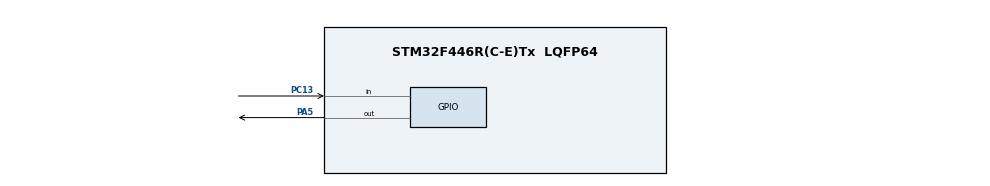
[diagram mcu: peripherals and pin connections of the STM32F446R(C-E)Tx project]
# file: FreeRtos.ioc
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FREERTOS.Mutexes01=myMutex01,Dynamic,NULL
FREERTOS.Tasks01=Task1,40,128,StartTask1,Default,NULL,Dynamic,NULL,NULL;Task2,24,128,StartTask2,Default,NULL,Dynamic,NULL,NULL;Task3,8,128,StartTask3,Default,NULL,Dynamic,NULL,NULL
Mcu.Family=STM32F4
Mcu.Name=STM32F446R(C-E)Tx
Mcu.Package=LQFP64
NVIC.PriorityGroup=NVIC_PRIORITYGROUP_4
NVIC.TIM6_DAC_IRQn=true\:15\:0\:false\:false\:true\:false\:false\:true\:true
NVIC.TimeBase=TIM6_DAC_IRQn
NVIC.TimeBaseIP=TIM6
PA13.Mode=Trace_Asynchronous_SW
PA13.Signal=SYS_JTMS-SWDIO
PA14.Mode=Trace_Asynchronous_SW
PA14.Signal=SYS_JTCK-SWCLK
PA5.Signal=GPIO_Output
PB3.Mode=Trace_Asynchronous_SW
PB3.Signal=SYS_JTDO-SWO
PC13.Signal=GPIO_Input
ProjectManager.HeapSize=0x200
ProjectManager.StackSize=0x400
ProjectManager.TargetToolchain=STM32CubeIDE
RCC.CortexFreq_Value=16000000
RCC.USBFreq_Value=96000000
RCC.VCOOutputFreq_Value=192000000
VP_FREERTOS_VS_CMSIS_V2.Mode=CMSIS_V2
VP_SYS_VS_tim6.Mode=TIM6
board=custom

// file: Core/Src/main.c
/* USER CODE BEGIN Header */
/**
  ******************************************************************************
  * @file           : main.c
  * @brief          : Main program body
  ******************************************************************************
  * @attention
  *
  * Copyright (c) 2024 STMicroelectronics.
  * All rights reserved.
  *
  * This software is licensed under terms that can be found in the LICENSE file
  * in the root directory of this software component.
  * If no LICENSE file comes with this software, it is provided AS-IS.
  *
  ******************************************************************************
  */
/* USER CODE END Header */
#include "main.h"
#include "cmsis_os.h"

/* USER CODE BEGIN Includes */
#include <stdio.h>

/* USER CODE END Includes */

/* Definitions for Task1 */
osThreadId_t Task1Handle;
const osThreadAttr_t Task1_attributes = {
  .name = "Task1",
  .stack_size = 128 * 4,
  .priority = (osPriority_t) osPriorityHigh,
};
/* Definitions for Task2 */
osThreadId_t Task2Handle;
const osThreadAttr_t Task2_attributes = {
  .name = "Task2",
  .stack_size = 128 * 4,
  .priority = (osPriority_t) osPriorityNormal,
};
/* Definitions for Task3 */
osThreadId_t Task3Handle;
const osThreadAttr_t Task3_attributes = {
  .name = "Task3",
  .stack_size = 128 * 4,
  .priority = (osPriority_t) osPriorityLow,
};
/* Definitions for myMutex01 */
osMutexId_t myMutex01Handle;
const osMutexAttr_t myMutex01_attributes = {
  .name = "myMutex01"
};

void SystemClock_Config(void);
static void MX_GPIO_Init(void);
void StartTask1(void *argument);
void StartTask2(void *argument);
void StartTask3(void *argument);

typedef uint8_t TaskProfiler;
TaskProfiler Task1_Profiler, Task2_Profiler, Task3_Profiler;

int main(void)
{

  /* MCU Configuration--------------------------------------------------------*/

  /* Reset of all peripherals, Initializes the Flash interface and the Systick. */
  HAL_Init();

  /* Configure the system clock */
  SystemClock_Config();

  /* Initialize all configured peripherals */
  MX_GPIO_Init();

  /* Init scheduler */
  osKernelInitialize();

  /* Create the thread(s) */
  /* creation of Task1 */
  Task1Handle = osThreadNew(StartTask1, NULL, &Task1_attributes);

  /* creation of Task2 */
  Task2Handle = osThreadNew(StartTask2, NULL, &Task2_attributes);

  /* creation of Task3 */
  Task3Handle = osThreadNew(StartTask3, NULL, &Task3_attributes);

  /* Start scheduler */
  osKernelStart();

  /* We should never get here as control is now taken by the scheduler */
  /* Infinite loop */
  while (1)
  {

  }
}

void SystemClock_Config(void)
{
  RCC_OscInitTypeDef RCC_OscInitStruct = {0};
  RCC_ClkInitTypeDef RCC_ClkInitStruct = {0};

  /** Configure the main internal regulator output voltage
  */
  __HAL_RCC_PWR_CLK_ENABLE();
  __HAL_PWR_VOLTAGESCALING_CONFIG(PWR_REGULATOR_VOLTAGE_SCALE3);

  /** Initializes the RCC Oscillators according to the specified parameters
  * in the RCC_OscInitTypeDef structure.
  */
  RCC_OscInitStruct.OscillatorType = RCC_OSCILLATORTYPE_HSI;
  RCC_OscInitStruct.HSIState = RCC_HSI_ON;
  RCC_OscInitStruct.HSICalibrationValue = RCC_HSICALIBRATION_DEFAULT;
  RCC_OscInitStruct.PLL.PLLState = RCC_PLL_NONE;
  if (HAL_RCC_OscConfig(&RCC_OscInitStruct) != HAL_OK)
  {
    Error_Handler();
  }

  /** Initializes the CPU, AHB and APB buses clocks
  */
  RCC_ClkInitStruct.ClockType = RCC_CLOCKTYPE_HCLK|RCC_CLOCKTYPE_SYSCLK
                              |RCC_CLOCKTYPE_PCLK1|RCC_CLOCKTYPE_PCLK2;
  RCC_ClkInitStruct.SYSCLKSource = RCC_SYSCLKSOURCE_HSI;
  RCC_ClkInitStruct.AHBCLKDivider = RCC_SYSCLK_DIV1;
  RCC_ClkInitStruct.APB1CLKDivider = RCC_HCLK_DIV1;
  RCC_ClkInitStruct.APB2CLKDivider = RCC_HCLK_DIV1;

  if (HAL_RCC_ClockConfig(&RCC_ClkInitStruct, FLASH_LATENCY_0) != HAL_OK)
  {
    Error_Handler();
  }
}

static void MX_GPIO_Init(void)
{
  GPIO_InitTypeDef GPIO_InitStruct = {0};

  /* GPIO Ports Clock Enable */
  __HAL_RCC_GPIOC_CLK_ENABLE();
  __HAL_RCC_GPIOA_CLK_ENABLE();
  __HAL_RCC_GPIOB_CLK_ENABLE();

  /*Configure GPIO pin Output Level */
  HAL_GPIO_WritePin(GPIOA, GPIO_PIN_5, GPIO_PIN_RESET);

  /*Configure GPIO pin : PC13 */
  GPIO_InitStruct.Pin = GPIO_PIN_13;
  GPIO_InitStruct.Mode = GPIO_MODE_INPUT;
  GPIO_InitStruct.Pull = GPIO_NOPULL;
  HAL_GPIO_Init(GPIOC, &GPIO_InitStruct);

  /*Configure GPIO pin : PA5 */
  GPIO_InitStruct.Pin = GPIO_PIN_5;
  GPIO_InitStruct.Mode = GPIO_MODE_OUTPUT_PP;
  GPIO_InitStruct.Pull = GPIO_NOPULL;
  GPIO_InitStruct.Speed = GPIO_SPEED_FREQ_LOW;
  HAL_GPIO_Init(GPIOA, &GPIO_InitStruct);

}

void StartTask1(void *argument)
{
  /* USER CODE BEGIN 5 */
  /* Infinite loop */
  for(;;)
  {
	  int c;
	  c = Task1_Profiler++;
	  printf("Task-1 %d \n", c);
	 if (c >= 3) {
	 osThreadExit();
	  }
  }
  /* USER CODE END 5 */
}

void StartTask2(void *argument)
{
  /* USER CODE BEGIN StartTask2 */
  /* Infinite loop */

	// Get the current time
  for(;;)
  {
	    int c;
	    c = Task2_Profiler++;
	    printf("Task-2 %d \n", c);
	    if (c >= 3) {
	    osThreadExit();
	         }
	     }

    //osDelay(1000);
  }
  /* USER CODE END StartTask2 */

void StartTask3(void *argument)
{
  /* USER CODE BEGIN StartTask3 */
  /* Infinite loop */
  for(;;)
  {
	    int c;
	    c = Task3_Profiler++;
	    printf("Task-3 %d \n", c);
	    if (c >= 3) {
	    osThreadExit();
	         }

	      }

    //osDelay(1);
  }
  /* USER CODE END StartTask3 */

void HAL_TIM_PeriodElapsedCallback(TIM_HandleTypeDef *htim)
{
  if (htim->Instance == TIM6) {
    HAL_IncTick();
  }
}

void Error_Handler(void)
{
  __disable_irq();
  while (1)
  {
  }
}
